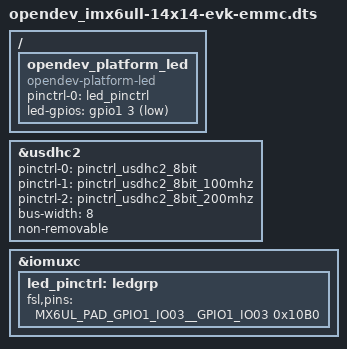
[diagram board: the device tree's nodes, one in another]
/*
 * Copyright 2019 NXP
 *
 * This program is free software; you can redistribute it and/or
 * modify it under the terms of the GNU General Public License
 * as published by the Free Software Foundation; either version 2
 * of the License, or (at your option) any later version.
 */

#include "imx6ull-14x14-evk.dts"

&usdhc2 {
	pinctrl-names = "default", "state_100mhz", "state_200mhz";
	pinctrl-0 = <&pinctrl_usdhc2_8bit>;
	pinctrl-1 = <&pinctrl_usdhc2_8bit_100mhz>;
	pinctrl-2 = <&pinctrl_usdhc2_8bit_200mhz>;
	bus-width = <8>;
	non-removable;
	status = "okay";
};

// &iomuxc {
// 	pinctrl_test: testgrp {
// 		fsl,pins = <
// 		MX6UL_PAD_GPIO1_IO00__GPIO1_IO00 config /* config 是具体设置的值 */
// 		>;
// 	};
// };

// 使用 pinctrl 和 GPIO 子系统的方式
&iomuxc {
	led_pinctrl: ledgrp {
		fsl,pins = <
			MX6UL_PAD_GPIO1_IO03__GPIO1_IO03 0x10B0 /* GPIO1_IO03 LED0 */
		>;
	};
};

// 使用 platform 总线的方式，在设备树中定义则会自动转成 platform 的设备结构体
/ {
	opendev_platform_led {
		#address-cells = <1>;
		#size-cells = <1>;
		compatible = "opendev-platform-led";
		pinctrl-names = "default";
		pinctrl-0 = <&led_pinctrl>;
		led-gpios = <&gpio1 3 GPIO_ACTIVE_LOW>;
		status = "okay";
	}
}
